# STM32L15xxE register map
File version: 1.0
CPU: 
Registers are 32-bit, read-write, reset 0x0 unless marked. A register's access mark holds for its fields unless they carry their own. Offsets are from the block's base; [hi:lo] are bit positions; {n}, {i} and the like mark numbered series.

## TIM6 — Basic timers
Base 0x40001000
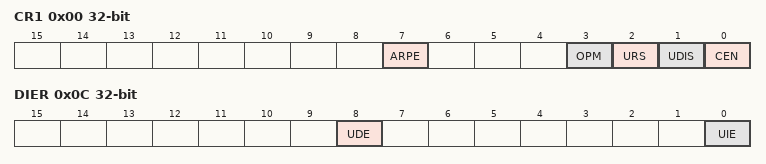
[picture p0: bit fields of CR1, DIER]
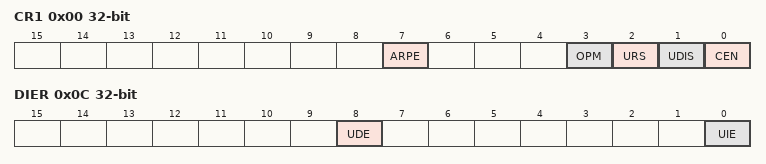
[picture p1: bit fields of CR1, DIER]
0x00 CR1 — TIM6 control register 1
  [7] ARPE — Auto-reload preload enable
  [3] OPM — One-pulse mode
  [2] URS — Update request source
  [1] UDIS — Update disable
  [0] CEN — Counter enable
0x04 CR2 — TIM6 control register 2
  [6:4] MMS — Master mode selection
0x0C DIER — TIM6 DMA/Interrupt enable register
  [8] UDE — Update DMA request enable
  [0] UIE — Update interrupt enable
0x10 SR — TIM6 status register
  [0] UIF — Update interrupt flag
0x14 EGR wo — TIM6 event generation register
  [0] UG — Update generation
0x24 CNT — TIM6 counter
  [15:0] CNT
0x28 PSC — TIM6 prescaler
  [15:0] PSC — Prescaler valueThe counter clock frequency CK_CNT is equal to fCK_PSC / (PSC[15:0] + 1).
0x2C ARR — TIM6 auto-reload register
  [15:0] ARR — Prescaler value

## TIM7 — Basic timers
Base 0x40001400
0x00 CR1 — TIM6 control register 1
  [7] ARPE — Auto-reload preload enable
  [3] OPM — One-pulse mode
  [2] URS — Update request source
  [1] UDIS — Update disable
  [0] CEN — Counter enable
0x04 CR2 — TIM6 control register 2
  [6:4] MMS — Master mode selection
0x0C DIER — TIM6 DMA/Interrupt enable register
  [8] UDE — Update DMA request enable
  [0] UIE — Update interrupt enable
0x10 SR — TIM6 status register
  [0] UIF — Update interrupt flag
0x14 EGR wo — TIM6 event generation register
  [0] UG — Update generation
0x24 CNT — TIM6 counter
  [15:0] CNT
0x28 PSC — TIM6 prescaler
  [15:0] PSC — Prescaler valueThe counter clock frequency CK_CNT is equal to fCK_PSC / (PSC[15:0] + 1).
0x2C ARR — TIM6 auto-reload register
  [15:0] ARR — Prescaler value

## C_ADC — Common ADC registers
Base 0x40012700
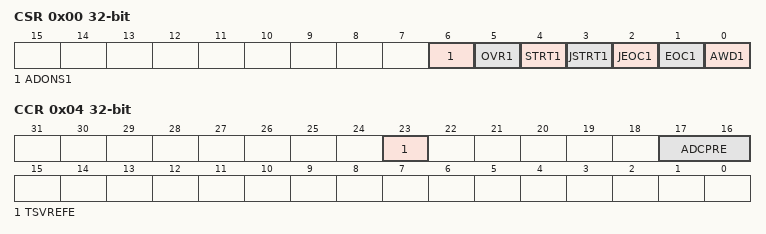
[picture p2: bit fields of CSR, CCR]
0x00 CSR ro — ADC Common status register
  [6] ADONS1 — ADON Status of ADC
  [5] OVR1 — Overrun flag of ADC 1
  [4] STRT1 — Regular channel Start flag of ADC 1
  [3] JSTRT1 — Injected channel Start flag of ADC 1
  [2] JEOC1 — Injected channel end of conversion of ADC 1
  [1] EOC1 — End of conversion of ADC 1
  [0] AWD1 — Analog watchdog flag of ADC 1
0x04 CCR — ADC common control register
  [23] TSVREFE — Temperature sensor and VREFINT enable
  [17:16] ADCPRE — ADC prescaler

## COMP — Comparators
Base 0x40007C00
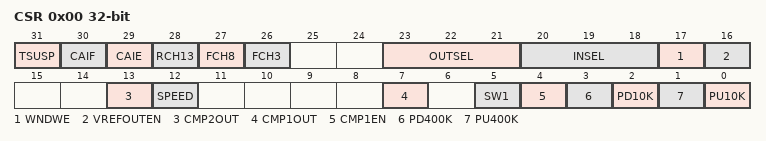
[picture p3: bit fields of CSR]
0x00 CSR access per field — comparator control and status register
  [31] TSUSP rw — Suspend Timer Mode
  [30] CAIF ro — Channel acquisition interrupt flag
  [29] CAIE rw — Channel Acquisition Interrupt Enable / Clear
  [28] RCH13 rw — Select GPIO port PC3 as re-routed ADC input channel CH13.
  [27] FCH8 rw — Select GPIO port PB0 as fast ADC input channel CH8.
  [26] FCH3 rw — Select GPIO port PA3 as fast ADC input channel CH3.
  [23:21] OUTSEL rw — Comparator 2 output selection
  [20:18] INSEL rw — Inverted input selection
  [17] WNDWE rw — Window mode enable
  [16] VREFOUTEN rw — VREFINT output enable
  [13] CMP2OUT ro — Comparator 2 output
  [12] SPEED rw — Comparator 2 speed mode
  [7] CMP1OUT ro — Comparator 1 output
  [5] SW1 rw — SW1 analog switch enable
  [4] CMP1EN rw — Comparator 1 enable
  [3] PD400K rw — 400 kO pull-down resistor
  [2] PD10K rw — 10 kO pull-down resistor
  [1] PU400K rw — 400 kO pull-up resistor
  [0] PU10K rw — 10 kO pull-up resistor

## CRC — CRC calculation unit
Base 0x40023000
0x00 DR reset 0xFFFFFFFF — Data register
  [31:0] Data_register
0x04 IDR — Independent data register
  [6:0] Independent_data_register
0x08 CR wo — Control register
  [0] RESET

## DBG — Debug support
Base 0xE0042000
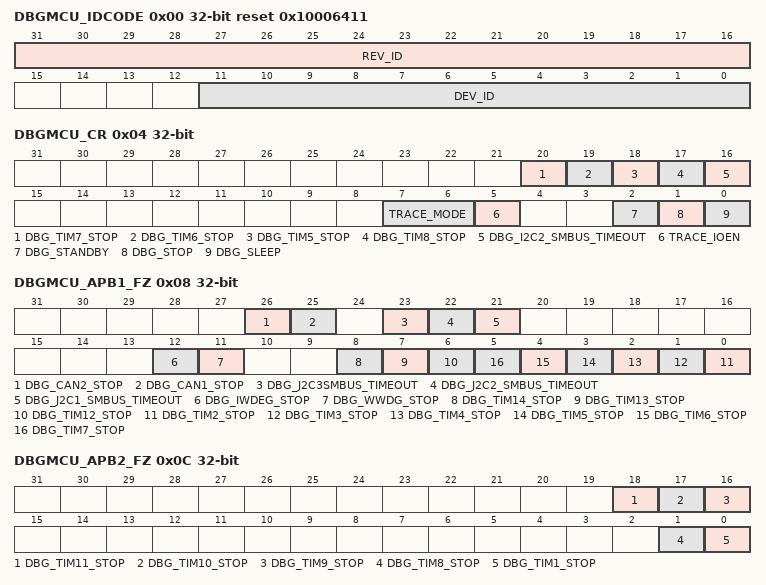
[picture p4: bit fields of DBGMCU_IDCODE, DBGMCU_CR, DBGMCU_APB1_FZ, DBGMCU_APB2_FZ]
0x00 DBGMCU_IDCODE ro reset 0x10006411 — IDCODE
  [31:16] REV_ID, [11:0] DEV_ID
0x04 DBGMCU_CR — Control Register
  [20] DBG_TIM7_STOP, [19] DBG_TIM6_STOP, [18] DBG_TIM5_STOP, [17] DBG_TIM8_STOP, [16] DBG_I2C2_SMBUS_TIMEOUT, [7:6] TRACE_MODE, [5] TRACE_IOEN, [2] DBG_STANDBY, [1] DBG_STOP, [0] DBG_SLEEP
0x08 DBGMCU_APB1_FZ — Debug MCU APB1 Freeze registe
  [26] DBG_CAN2_STOP, [25] DBG_CAN1_STOP, [23] DBG_J2C3SMBUS_TIMEOUT, [22] DBG_J2C2_SMBUS_TIMEOUT, [21] DBG_J2C1_SMBUS_TIMEOUT, [12] DBG_IWDEG_STOP, [11] DBG_WWDG_STOP, [8] DBG_TIM14_STOP, [7] DBG_TIM13_STOP, [6] DBG_TIM12_STOP, [n-2] DBG_TIM{n}_STOP (n=2..7)
0x0C DBGMCU_APB2_FZ — Debug MCU APB2 Freeze registe
  [18] DBG_TIM11_STOP — TIM11 counter stopped when core is halted
  [17] DBG_TIM10_STOP — TIM10 counter stopped when core is halted
  [16] DBG_TIM9_STOP — TIM9 counter stopped when core is halted
  [1] DBG_TIM8_STOP — TIM8 counter stopped when core is halted
  [0] DBG_TIM1_STOP — TIM1 counter stopped when core is halted
